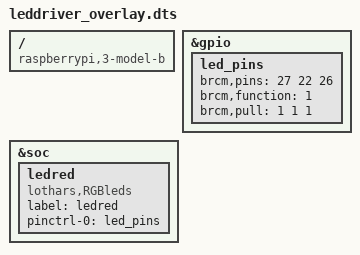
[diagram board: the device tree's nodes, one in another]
/dts-v1/;
/plugin/;
/ {
	compatible = "raspberrypi,3-model-b", "brcm,bcm2835";
        fragment@0 {
		target = <&gpio>;
		__overlay__ {
			// leds: gpios
			led_pins: led_pins {
				brcm,pins = <27 22 26>;
				brcm,function = <1>;   /* output */
				brcm,pull = <1 1 1>;   /* pull down */
			};
		 };
	};

	fragment@1 {
		target = <&soc>;
		__overlay__ {
			// leds: colors
			ledred {
				compatible = "lothars,RGBleds";
				label = "ledred";
				pinctrl-0 = <&led_pins>;
			};

			/*
			NB: the other colors are turned off

			when turned on, we will see Oops for attempts to re-establish
			yet another lothar_device for each color, try it!
			*/
//			ledgreen {
//				compatible = "lothars,RGBleds";
//				label = "ledgreen";
//				pinctrl-0 = <&led_pins>;
//			};
//
//			ledblue {
//				compatible = "lothars,RGBleds";
//				label = "labelblue";
//				pinctrl-0 = <&led_pins>;
//			};
		 };
	};
};
